# AVR32EA48 register map
Vendor: Atmel; File version: 1.0
CPU: other r0p0, little endian, no MPU, no FPU, 4 interrupt priority bits
Registers are 8-bit, read-write, reset 0x0 unless marked. A register's access mark holds for its fields unless they carry their own. Offsets are from the block's base; [hi:lo] are bit positions; {n}, {i} and the like mark numbered series; 'fields as' and 'values as' point back to an identical list.

## GPR — General Purpose Registers
Base 0x0080001C
{0x0+i} GPR{i} (i=0..3) — General Purpose Register {i}

## LOCK — Lockbits
Base 0x00801040
0x00 KEY 32-bit (reset mask 0xFF) — Lock Key Bits
  [31:0] KEY — Lock Key
    0x5CC5C55C=NOLOCK (No locks); 0xA33A3AA3=RWLOCK (Read and write lock)

## NVMCTRL — Non-volatile Memory Controller
Base 0x00801000
0x00 CTRLA — Control A
  [6:0] CMD — Command
    0=NOCMD (No Command); 1=NOOP (No Operation); 4=FLPW (Flash Page Write); 5=FLPERW (Flash Page Erase and Write); 8=FLPER (Flash Page Erase); 9=FLMPER2 (Flash 2-page erase enable); 10=FLMPER4 (Flash 4-page erase enable); 11=FLMPER8 (Flash 8-page erase enable); 12=FLMPER16 (Flash 16-page erase enable); 13=FLMPER32 (Flash 32-page erase enable); 15=FLPBCLR (Flash Page Buffer Clear); 20=EEPW (EEPROM Page Write); 21=EEPERW (EEPROM Page Erase and Write); 23=EEPER (EEPROM Page Erase); 31=EEPBCLR (EEPROM Page Buffer Clear); 32=CHER (Chip Erase Command (UPDI only)); 48=EECHER (EEPROM Erase Command (UPDI only))
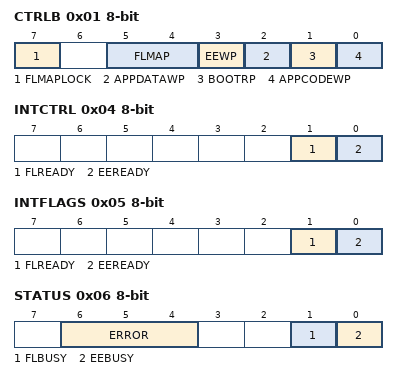
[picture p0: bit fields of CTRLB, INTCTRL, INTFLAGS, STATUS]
0x01 CTRLB — Control B
  [7] FLMAPLOCK — Flash Mapping Lock
  [5:4] FLMAP — Flash Mapping in Data space
    0=SECTION0 (Flash section 0, 0 - 32KB); 1=SECTION1 (Flash section 1, 32 - 64KB); 2=SECTION2 (Flash section 2, 64 - 96KB); 3=SECTION3 (Flash section 3, 96 - 128KB)
  [3] EEWP — EEPROM Write Protect
  [2] APPDATAWP — Application Data Write Protect
  [1] BOOTRP — Boot Read Protect
  [0] APPCODEWP — Application Code Write Protect
0x04 INTCTRL — Interrupt Control
  [1] FLREADY — Flash Ready
  [0] EEREADY — EEPROM Ready
0x05 INTFLAGS — Interrupt Flags
  [1] FLREADY — Flash Ready
  [0] EEREADY — EEPROM Ready
0x06 STATUS
  [6:4] ERROR — Write error
    0=NOERROR; 2=WRITEPROTECT (Attempt to program write protected area); 3=CMDCOLLISION (Selecting new write command while write command already seleted); 4=WRONGSECTION (Address cannot be written with selected command)
  [1] FLBUSY ro — Flash busy
  [0] EEBUSY ro — EEPROM busy
0x08 DATA 16-bit (reset mask 0xFF)
0x0C ADDR 32-bit (reset mask 0xFF) — Address
  [23:0] ADDR

## PORTA — I/O Ports
Base 0x00800400
Same registers: PORTB 0x00800420, PORTD 0x00800460, PORTE 0x00800480, PORTF 0x008004A0
0x00 DIR — Data Direction
0x01 DIRSET — Data Direction Set
0x02 DIRCLR — Data Direction Clear
0x03 DIRTGL — Data Direction Toggle
0x04 OUT — Output Value
0x05 OUTSET — Output Value Set
0x06 OUTCLR — Output Value Clear
0x07 OUTTGL — Output Value Toggle
0x08 IN — Input Value
0x09 INTFLAGS — Interrupt Flags
  [7:0] INT — Pin Interrupt Flag
0x0A PORTCTRL — Port Control
  [0] SRL — Slew Rate Limit Enable
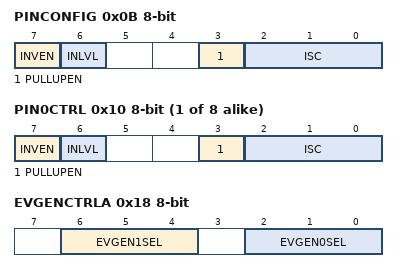
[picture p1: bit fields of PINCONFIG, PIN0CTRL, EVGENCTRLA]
0x0B PINCONFIG — Pin Control Config
  [7] INVEN — Inverted I/O Enable
  [6] INLVL — Input Level Select
    0=ST (Schmitt-Trigger input level); 1=TTL (TTL Input level)
  [3] PULLUPEN — Pullup enable
  [2:0] ISC — Input/Sense Configuration
    0=INTDISABLE (Interrupt disabled but input buffer enabled); 1=BOTHEDGES (Sense Both Edges); 2=RISING (Sense Rising Edge); 3=FALLING (Sense Falling Edge); 4=INPUT_DISABLE (Digital Input Buffer disabled); 5=LEVEL (Sense low Level)
0x0C PINCTRLUPD — Pin Control Update
0x0D PINCTRLSET — Pin Control Set
0x0E PINCTRLCLR — Pin Control Clear
{0x10+i} PIN{i}CTRL (i=0..7) — Pin {i} Control
  fields as PINCONFIG
0x18 EVGENCTRLA — Event Generation Control A
  [6:4] EVGEN1SEL — Event Generator 1 Select
    {v}=PIN{v} (Pin {v} used as event generator) (v=0..7)
  [2:0] EVGEN0SEL — Event Generator 0 Select
    {v}=PIN{v} (Pin {v} used as event generator) (v=0..7)

## PORTC — I/O Ports
Base 0x00800440
Registers as PORTA, without PORTCTRL; these are added or differ:
0x0A PORTCTRL — Port Control
  [0] SRL — Slew Rate Limit Enable
